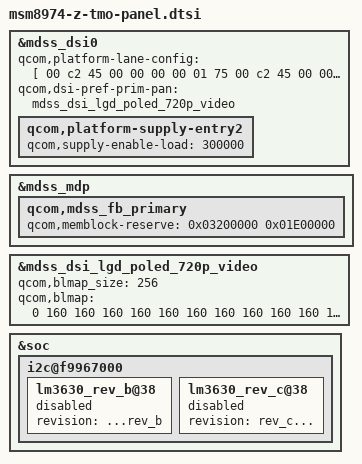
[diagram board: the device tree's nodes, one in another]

/* Copyright (c) 2012, Code Aurora Forum. All rights reserved.
 *
 * This program is free software; you can redistribute it and/or modify
 * it under the terms of the GNU General Public License version 2 and
 * only version 2 as published by the Free Software Foundation.
 *
 * This program is distributed in the hope that it will be useful,
 * but WITHOUT ANY WARRANTY; without even the implied warranty of
 * MERCHANTABILITY or FITNESS FOR A PARTICULAR PURPOSE.  See the
 * GNU General Public License for more details.
 */

&mdss_dsi0 {
	qcom,platform-lane-config = [
		00 c2 45 00 00 00 00 01 75 // lane0 config
		00 c2 45 00 00 00 00 01 75 // lane1 config
		00 c2 45 00 00 00 00 01 75 // lane2 config
		00 c2 45 00 00 00 00 01 75 // lane3 config
		00 02 45 00 00 00 00 01 97 // Clk ln config
	];
	qcom,dsi-pref-prim-pan = <&mdss_dsi_lgd_poled_720p_video>;
	qcom,platform-supply-entry2 {
		qcom,supply-enable-load = <300000>;
	};

};

&mdss_mdp {
	qcom,mdss_fb_primary {
		qcom,memblock-reserve = <0x03200000 0x01E00000>;
	};
};

&mdss_dsi_lgd_poled_720p_video {
	qcom,blmap_size = <256>;
	qcom,blmap = <
		0
		// unused area(001-054)
		160 160 160 160 160 160 160 160 160 160 160 160 160 160 160
		160 160 160 160 160 160 160 160 160 160 160 160 160 160 160
		160 160 160 160 160 160 160 160 160 160 160 160 160 160 160
		160 160 160 160 160 160 160 160 160
		// used area(055-255)
		178 178 178 178 178 178 178 178 179 179 179 179 179 179 179		// 055-069
		179 180 180 180 180 180 180 180 180 181 181 181 181 181 181		// 070-084
		182 182 182 182 182 182 183 183 183 183 183 183 184 184 184		// 085-099
		185 185 185 186 186 186 187 187 187 188 188 188 188 189 189		// 100-114
		189 190 190 190 191 191 191 192 192 192 193 193 193 194 194		// 115-129
		194 195 195 195 196 196 196 197 197 198 199 200 201 202 203		// 130-144
		204 205 206 207 207 208 209 209 210 211 212 212 212 212 212		// 145-159
		213 213 213 213 213 213 213 213 213 214 214 214 214 214 214		// 160-174
		214 214 215 216 217 218 219 220 221 222 223 223 224 225 225		// 175-189
		226 226 227 227 227 228 228 229 229 229 230 230 230 231 231		// 190-204
		231 231 232 232 232 232 232 233 233 234 234 234 235 235 235		// 205-219
		236 236 236 237 237 238 238 239 240 240 241 242 242 243 243		// 220-234
		244 244 245 246 246 247 248 248 249 249 250 250 251 252 252		// 235-249
		253 253 254 254 255 255											// 250-255
	>;
};

&soc {
	i2c@f9967000 {
		lm3630_rev_b@38 {
			status = "disable";
			revision = "...rev_b";
		};

		lm3630_rev_c@38 {
			status = "disable";
			revision = "rev_c...";
		};
	};
};
